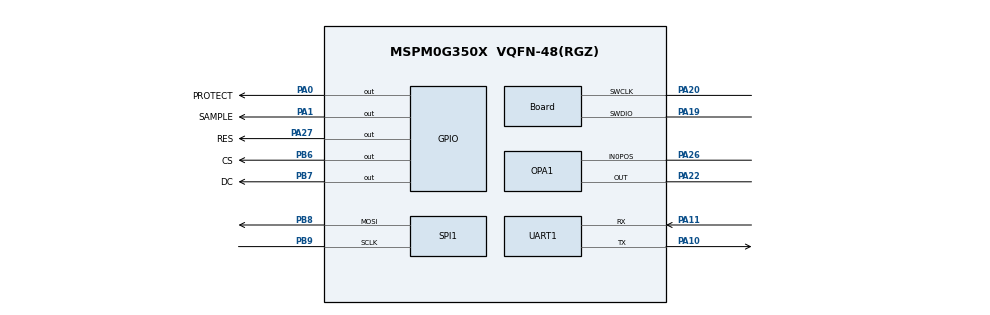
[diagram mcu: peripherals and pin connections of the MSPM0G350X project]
/**
 *
 * @cliArgs --device "MSPM0G350X" --part "Default" --package "VQFN-48(RGZ)" --product "mspm0_sdk@2.08.00.03"
 * @versions {"tool":"1.28.0+4712"}
 */

/**
 * Import the modules used in this configuration.
 */
const ADC12         = scripting.addModule("/ti/driverlib/ADC12", {}, false);
const ADC121        = ADC12.addInstance();
const Board         = scripting.addModule("/ti/driverlib/Board");
const COMP          = scripting.addModule("/ti/driverlib/COMP", {}, false);
const COMP1         = COMP.addInstance();
const GPIO          = scripting.addModule("/ti/driverlib/GPIO", {}, false);
const GPIO1         = GPIO.addInstance();
const GPIO2         = GPIO.addInstance();
const GPIO3         = GPIO.addInstance();
const OPA           = scripting.addModule("/ti/driverlib/OPA", {}, false);
const OPA1          = OPA.addInstance();
const SPI           = scripting.addModule("/ti/driverlib/SPI", {}, false);
const SPI1          = SPI.addInstance();
const SYSCTL        = scripting.addModule("/ti/driverlib/SYSCTL");
const TIMER         = scripting.addModule("/ti/driverlib/TIMER", {}, false);
const TIMER1        = TIMER.addInstance();
const TIMER2        = TIMER.addInstance();
const UART          = scripting.addModule("/ti/driverlib/UART", {}, false);
const UART1         = UART.addInstance();
const VREF          = scripting.addModule("/ti/driverlib/VREF");
const ProjectConfig = scripting.addModule("/ti/project_config/ProjectConfig");

/**
 * Write custom configuration values to the imported modules.
 */
const divider4       = system.clockTree["PLL_CLK0_DIV"];
divider4.divideValue = 32;

const divider7       = system.clockTree["PLL_PDIV"];
divider7.divideValue = 8;

const divider9       = system.clockTree["UDIV"];
divider9.divideValue = 2;

const multiplier2         = system.clockTree["PLL_QDIV"];
multiplier2.multiplyValue = 36;

const mux8       = system.clockTree["HSCLKMUX"];
mux8.inputSelect = "HSCLKMUX_SYSPLL0";

ADC121.adcMem0chansel                    = "DL_ADC12_INPUT_CHAN_13";
ADC121.enabledInterrupts                 = ["DL_ADC12_INTERRUPT_DMA_DONE"];
ADC121.configureDMA                      = true;
ADC121.sampCnt                           = 1;
ADC121.$name                             = "ADC_Current";
ADC121.enabledDMATriggers                = ["DL_ADC12_DMA_MEM0_RESULT_LOADED"];
ADC121.adcMem0vref                       = "VREF";
ADC121.sampleTime0                       = "0.5 ms";
ADC121.repeatMode                        = true;
ADC121.sampClkDiv                        = "DL_ADC12_CLOCK_DIVIDE_32";
ADC121.peripheral.$assign                = "ADC0";
ADC121.DMA_CHANNEL.$name                 = "DMA_CH0";
ADC121.DMA_CHANNEL.configureTransferSize = true;
ADC121.DMA_CHANNEL.srcLength             = "HALF_WORD";
ADC121.DMA_CHANNEL.dstLength             = "HALF_WORD";
ADC121.DMA_CHANNEL.addressMode           = "f2b";
ADC121.DMA_CHANNEL.transferSize          = 400;

Board.configureUnused             = true;
Board.unusedDirection             = "INPUT";
Board.unusedInternalResistor      = "PULL_DOWN";
Board.peripheral.$assign          = "DEBUGSS";
Board.peripheral.swclkPin.$assign = "PA20";
Board.peripheral.swdioPin.$assign = "PA19";

COMP1.$name                          = "COMP_0";
COMP1.compMode                       = "DL_COMP_MODE_ULP";
COMP1.hysteresis                     = "DL_COMP_HYSTERESIS_30";
COMP1.vSource                        = "DL_COMP_REF_SOURCE_VREF_DAC";
COMP1.controlSelect                  = "DL_COMP_DAC_CONTROL_SW";
COMP1.terminalSelect                 = "DL_COMP_REF_TERMINAL_SELECT_NEG";
COMP1.channelEnable                  = ["POS"];
COMP1.posChannel                     = "DL_COMP_IPSEL_CHANNEL_2";
COMP1.enableWinComp                  = true;
COMP1.setDACCode0                    = 0x98;
COMP1.peripheral.$assign             = "COMP0";
COMP1.peripheral.compPinPos2.$assign = "PA14";
COMP1.compPinPos2Config.$name        = "ti_driverlib_gpio_GPIOPinGeneric0";

GPIO1.$name                           = "OLED";
GPIO1.associatedPins.create(4);
GPIO1.associatedPins[0].$name         = "DC";
GPIO1.associatedPins[0].assignedPort  = "PORTB";
GPIO1.associatedPins[0].assignedPin   = "7";
GPIO1.associatedPins[0].pin.$assign   = "PB7";
GPIO1.associatedPins[1].$name         = "RES";
GPIO1.associatedPins[1].assignedPort  = "PORTA";
GPIO1.associatedPins[1].assignedPin   = "27";
GPIO1.associatedPins[1].pin.$assign   = "PA27";
GPIO1.associatedPins[2].$name         = "CS";
GPIO1.associatedPins[2].assignedPin   = "6";
GPIO1.associatedPins[2].pin.$assign   = "PB6";
GPIO1.associatedPins[3].driveStrength = "HIGH";
GPIO1.associatedPins[3].$name         = "VCC";

GPIO2.$name                          = "LED";
GPIO2.associatedPins[0].$name        = "D3";
GPIO2.associatedPins[0].assignedPort = "PORTA";
GPIO2.associatedPins[0].assignedPin  = "3";
GPIO2.associatedPins[0].initialValue = "SET";

GPIO3.$name                         = "MOS";
GPIO3.associatedPins.create(2);
GPIO3.associatedPins[0].$name       = "SAMPLE";
GPIO3.associatedPins[0].ioStructure = "OD";
GPIO3.associatedPins[0].pin.$assign = "PA1";
GPIO3.associatedPins[1].$name       = "PROTECT";
GPIO3.associatedPins[1].ioStructure = "OD";
GPIO3.associatedPins[1].pin.$assign = "PA0";

OPA1.$name                        = "OPA_0";
OPA1.cfg0PSELChannel              = "IN0_POS";
OPA1.cfg0MSELChannel              = "GND";
OPA1.cfg0OutputPin                = "ENABLED";
OPA1.cfg0Gain                     = "N1_P2";
OPA1.advRRI                       = true;
OPA1.cfg0NSELChannel              = "RTOP";
OPA1.In0PosPinConfig.$name        = "ti_driverlib_gpio_GPIOPinGeneric4";
OPA1.peripheral.In0PosPin.$assign = "PA26";
OPA1.peripheral.OutPin.$assign    = "PA22";
OPA1.OutPinConfig.$name           = "ti_driverlib_gpio_GPIOPinGeneric1";

SPI1.$name                      = "SPI_0";
SPI1.chipSelect                 = [];
SPI1.frameFormat                = "MOTO3";
SPI1.direction                  = "PICO";
SPI1.targetBitRate              = 2250000;
SPI1.sclkPinConfig.$name        = "ti_driverlib_gpio_GPIOPinGeneric2";
SPI1.mosiPinConfig.$name        = "ti_driverlib_gpio_GPIOPinGeneric3";
SPI1.peripheral.$assign         = "SPI1";
SPI1.peripheral.sclkPin.$assign = "PB9";
SPI1.peripheral.mosiPin.$assign = "PB8";

SYSCTL.MFCLKEn     = true;
SYSCTL.MFPCLKEn    = true;
SYSCTL.clockTreeEn = true;
SYSCTL.powerPolicy = "STOP2";

TIMER1.$name                       = "TIMER_0";
TIMER1.interrupts                  = ["ZERO"];
TIMER1.timerClkSrc                 = "LFCLK";
TIMER1.timerClkDiv                 = 8;
TIMER1.event1PublisherChannel      = 1;
TIMER1.event1ControllerInterruptEn = ["ZERO_EVENT"];
TIMER1.timerMode                   = "PERIODIC";
TIMER1.timerClkPrescale            = 256;
TIMER1.timerPeriod                 = "1.5 s";
TIMER1.peripheral.$assign          = "TIMG0";

TIMER2.$name                       = "TIMER_1";
TIMER2.timerClkSrc                 = "LFCLK";
TIMER2.timerClkDiv                 = 8;
TIMER2.timerPeriod                 = "10 ms";
TIMER2.interrupts                  = ["ZERO"];
TIMER2.event1PublisherChannel      = 2;
TIMER2.event1ControllerInterruptEn = ["ZERO_EVENT"];
TIMER2.timerClkPrescale            = 41;
TIMER2.peripheral.$assign          = "TIMG6";

UART1.$name                             = "UART_0";
UART1.targetBaudRate                    = 115200;
UART1.enabledDMATXTriggers              = "DL_UART_DMA_INTERRUPT_TX";
UART1.enabledDMARXTriggers              = "DL_UART_DMA_INTERRUPT_RX";
UART1.enabledInterrupts                 = ["DMA_DONE_TX","RX_TIMEOUT_ERROR"];
UART1.rxTimeoutValue                    = 15;
UART1.peripheral.$assign                = "UART0";
UART1.peripheral.rxPin.$assign          = "PA11";
UART1.peripheral.txPin.$assign          = "PA10";
UART1.txPinConfig.$name                 = "ti_driverlib_gpio_GPIOPinGeneric5";
UART1.rxPinConfig.$name                 = "ti_driverlib_gpio_GPIOPinGeneric8";
UART1.DMA_CHANNEL_TX.$name              = "DMA_CH1";
UART1.DMA_CHANNEL_TX.srcLength          = "BYTE";
UART1.DMA_CHANNEL_TX.dstLength          = "BYTE";
UART1.DMA_CHANNEL_TX.transferMode       = "FULL_CH_REPEAT_SINGLE";
UART1.DMA_CHANNEL_TX.peripheral.$assign = "DMA_CH1";
UART1.DMA_CHANNEL_RX.$name              = "DMA_CH2";

VREF.basicMode              = "DL_VREF_ENABLE_DISABLE";
VREF.checkVREFReady         = true;
VREF.basicExtVolt           = 3.3;
VREF.basicVrefPins          = "VREF+-";
VREF.vrefPosPinConfig.$name = "ti_driverlib_gpio_GPIOPinGeneric6";
VREF.vrefNegPinConfig.$name = "ti_driverlib_gpio_GPIOPinGeneric7";

ProjectConfig.migrationCondition = true;

/**
 * Pinmux solution for unlocked pins/peripherals. This ensures that minor changes to the automatic solver in a future
 * version of the tool will not impact the pinmux you originally saw.  These lines can be completely deleted in order to
 * re-solve from scratch.
 */
ADC121.DMA_CHANNEL.peripheral.$suggestSolution   = "DMA_CH2";
GPIO1.associatedPins[3].pin.$suggestSolution     = "PA28";
GPIO2.associatedPins[0].pin.$suggestSolution     = "PA3";
OPA1.peripheral.$suggestSolution                 = "OPA0";
UART1.DMA_CHANNEL_RX.peripheral.$suggestSolution = "DMA_CH0";
VREF.peripheral.$suggestSolution                 = "VREF";
VREF.peripheral.vrefPosPin.$suggestSolution      = "PA23";
VREF.peripheral.vrefNegPin.$suggestSolution      = "PA21";
